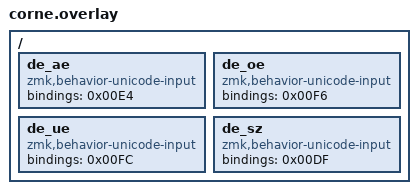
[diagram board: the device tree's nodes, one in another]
/ {
  de_ae: de_ae {
    compatible = "zmk,behavior-unicode-input";
    #binding-cells = <1>;
    bindings = <0x00E4>; // ä
  };

  de_oe: de_oe {
    compatible = "zmk,behavior-unicode-input";
    #binding-cells = <1>;
    bindings = <0x00F6>; // ö
  };

  de_ue: de_ue {
    compatible = "zmk,behavior-unicode-input";
    #binding-cells = <1>;
    bindings = <0x00FC>; // ü
  };

  de_sz: de_sz {
    compatible = "zmk,behavior-unicode-input";
    #binding-cells = <1>;
    bindings = <0x00DF>; // ß
  };
};
